AUTOSAR XML (schema 4-2-1)
package /ComponentTypes
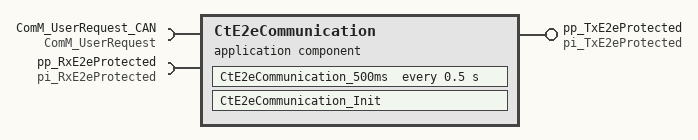
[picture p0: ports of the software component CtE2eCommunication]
  application sw component type CtE2eCommunication
    provide port pp_TxE2eProtected: nonqueued-sender-com-spec{data-element=sgTx_E2eProt, uses-end-to-end-protection=true, init-value=fields=[ElementConstant:0, ElementConstant_1:0, ElementConstant_2:0, ElementConstant_3:0, ElementConstant_4:0, ElementConstant_5:0, ElementConstant_6:0]}, provided-interface=pi_TxE2eProtected
    require port ComM_UserRequest_CAN: required-interface=ComM_UserRequest
    require port pp_RxE2eProtected: nonqueued-receiver-com-spec{data-element=sgRx_E2eProt, uses-end-to-end-protection=true, enable-update=true, filter=data-filter-type=ALWAYS, init-value=fields=[ElementConstant:0, ElementConstant_1:0, ElementConstant_2:0, ElementConstant_3:0, ElementConstant_4:0, ElementConstant_5:0]}, required-interface=pi_RxE2eProtected
    behavior CtE2eCommunication_InternalBehavior
      timing event TMT_CtE2eCommunication_500ms: start-on-event=CtE2eCommunication_500ms, period=0.5
      init event CtE2eCommunication_InitEvent: start-on-event=CtE2eCommunication_Init
      runnable CtE2eCommunication_500ms
        data-receive-point-by-arguments:
          access REC_pp_RxE2eProtected_sgRx_E2eProt: accessed-variable=pp_RxE2eProtected.sgRx_E2eProt
        data-send-points:
          access SEND_pp_TxE2eProtected_sgTx_E2eProt: accessed-variable=pp_TxE2eProtected.sgTx_E2eProt
        sync call SC_ComM_UserRequest_CAN_GetRequestedComMode: operation=ComM_UserRequest_CAN.GetRequestedComMode, timeout=0
      runnable CtE2eCommunication_Init
  swc implementation CtE2eCommunication_Implementation: behavior=CtE2eCommunication_InternalBehavior
    code-descriptors:
      code Default: artifact-descriptors=autosar-engineering-object={short-label=Default, category=SWSRC}
